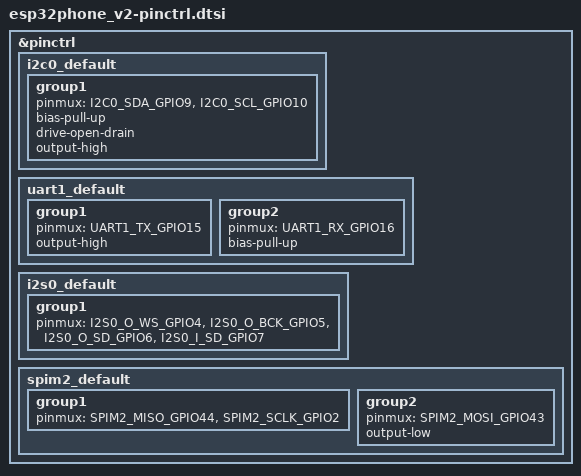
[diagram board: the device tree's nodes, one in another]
/*
 * esp32PhoneV2 Mainboard (PCB4) pin assignments.
 * Verified against HARDWARE/pcb/Mainboard_schematics.pdf (2026-01-02).
 */

#include <zephyr/dt-bindings/pinctrl/esp-pinctrl-common.h>
#include <zephyr/dt-bindings/pinctrl/esp32s3-pinctrl.h>
#include <zephyr/dt-bindings/pinctrl/esp32s3-gpio-sigmap.h>

&pinctrl {
	/* Shared bus: ST7567 LCD + TCA9555 keypad expander (EXT_PIN1/2 jumpers) */
	i2c0_default: i2c0_default {
		group1 {
			pinmux = <I2C0_SDA_GPIO9>,
				 <I2C0_SCL_GPIO10>;
			bias-pull-up;
			drive-open-drain;
			output-high;
		};
	};

	/* A7680C modem behind TXS0108E level shifter */
	uart1_default: uart1_default {
		group1 {
			pinmux = <UART1_TX_GPIO15>;
			output-high;
		};

		group2 {
			pinmux = <UART1_RX_GPIO16>;
			bias-pull-up;
		};
	};

	/*
	 * One full-duplex bus: MAX98357A (out) and PCM1809 (in) share
	 * BCLK/LRCLK. No MCLK line on this board.
	 */
	i2s0_default: i2s0_default {
		group1 {
			pinmux = <I2S0_O_WS_GPIO4>,
				 <I2S0_O_BCK_GPIO5>,
				 <I2S0_O_SD_GPIO6>,
				 <I2S0_I_SD_GPIO7>;
		};
	};

	/* micro-SD slot (TF1), SPI mode. Note: MOSI/MISO sit on the UART0
	 * pins (GPIO43/44), which is why the console is USB-Serial-JTAG. */
	spim2_default: spim2_default {
		group1 {
			pinmux = <SPIM2_MISO_GPIO44>,
				 <SPIM2_SCLK_GPIO2>;
		};

		group2 {
			pinmux = <SPIM2_MOSI_GPIO43>;
			output-low;
		};
	};
};
